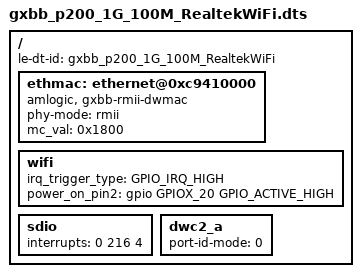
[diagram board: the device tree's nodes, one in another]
#include "gxbb_p200.dts"

/{
	le-dt-id = "gxbb_p200_1G_100M_RealtekWiFi";
	ethmac: ethernet@0xc9410000 {
		compatible = "amlogic, gxbb-rmii-dwmac";
		phy-mode= "rmii";
		mc_val = <0x1800>;
	};

	/delete-node/ bt-dev;

	wifi {
		irq_trigger_type = "GPIO_IRQ_HIGH";
		/delete-property/ dhd_static_buf;
		power_on_pin2 = <&gpio	   GPIOX_20	   GPIO_ACTIVE_HIGH>;
	};

	sdio {
		interrupts = <	0 216 4>;
	};

	dwc2_a {
		port-id-mode = <0>; /** 0: hardware, 1: sw_host, 2: sw_slave*/
		/delete-property/ gpio-vbus-power;
		/delete-property/ gpios;
	};
};
